AUTOSAR XML (schema 4-3-0)
standard types defined: sint16, uint16, uint8, sint16_DataConstr, uint16_DataConstr, uint8_DataConstr, boolean
package /IoHwAb/Interface
  client server interface IoHwAb_IoSigAdc
    operation Adc_Get: possible-error=E_NOT_OK
      arg id_u16: type=ImplementationDataTypes/uint16, direction=IN, server-argument-impl-policy=USE-ARGUMENT-TYPE
      arg val_s16: type=sint16, direction=OUT, server-argument-impl-policy=USE-ARGUMENT-TYPE
    operation AdcFac_Get: possible-error=E_NOT_OK
      arg id_u16: type=ImplementationDataTypes/uint16, direction=IN, server-argument-impl-policy=USE-ARGUMENT-TYPE
      arg val_s16: type=sint16, direction=OUT, server-argument-impl-policy=USE-ARGUMENT-TYPE
    operation AdcVRMBatt_Get: possible-error=E_NOT_OK
      arg id_u16: type=ImplementationDataTypes/uint16, direction=IN, server-argument-impl-policy=USE-ARGUMENT-TYPE
      arg val_u8: type=ImplementationDataTypes/uint8, direction=OUT, server-argument-impl-policy=USE-ARGUMENT-TYPE
    error E_NOT_OK: error-code=1
package /UAES/ASW/ApplicationDataTypes
  app type Fac_q0p001_u16: category=VALUE, sw-calibration-access=READ-WRITE, compu {phys=raw*0.001}, range phys 0..65.535
package /UAES/ASW/CompuMethods
  compu method CM_boolean: 0=FALSE, 1=TRUE
package /UAES/ASW/DataConstrs
  range DC_boolean: raw 0..1
  range DC_uint16: raw 0..65535
  range DC_uint8: raw 0..255
package /UAES/ASW/DataTypeMappingSets
  data type mapping set DTMS_PwrModMngt_DD: data-type-map{application-data-type=Fac_q0p001_u16, implementation-data-type=ImplementationDataTypes/uint16}
package /UAES/ASW/PortInterfaces
  7 x sender receiver interface:
    BattU_buExcdLrgRng: invalidation-policy{data-element=BattU_buExcdLrgRng/Val, handle-invalid=DONT-INVALIDATE}
      data Val: sw-calibration-access=READ-ONLY, type=boolean
    BattU_VrmFac1: invalidation-policy{data-element=BattU_VrmFac1/Val, handle-invalid=DONT-INVALIDATE}
      data Val: sw-calibration-access=READ-ONLY, type=Fac_q0p001_u16
    BattU_VrmFac2: invalidation-policy{data-element=BattU_VrmFac2/Val, handle-invalid=DONT-INVALIDATE}
      data Val: sw-calibration-access=READ-ONLY, type=Fac_q0p001_u16
    BattU_VrmFac3: invalidation-policy{data-element=BattU_VrmFac3/Val, handle-invalid=DONT-INVALIDATE}
      data Val: sw-calibration-access=READ-ONLY, type=Fac_q0p001_u16
    gPwrModMngt_u8RLSeatOccpdSwt: invalidation-policy{data-element=gPwrModMngt_u8RLSeatOccpdSwt/Val, handle-invalid=DONT-INVALIDATE}
      data Val: sw-calibration-access=READ-ONLY, type=ImplementationDataTypes/uint8
    gPwrModMngt_u8RMSeatOccpdSwt: invalidation-policy{data-element=gPwrModMngt_u8RMSeatOccpdSwt/Val, handle-invalid=DONT-INVALIDATE}
      data Val: sw-calibration-access=READ-ONLY, type=ImplementationDataTypes/uint8
    gPwrModMngt_u8RRSeatOccpdSwt: invalidation-policy{data-element=gPwrModMngt_u8RRSeatOccpdSwt/Val, handle-invalid=DONT-INVALIDATE}
      data Val: sw-calibration-access=READ-ONLY, type=ImplementationDataTypes/uint8
package /UAES/ASW/SwComponentTypes
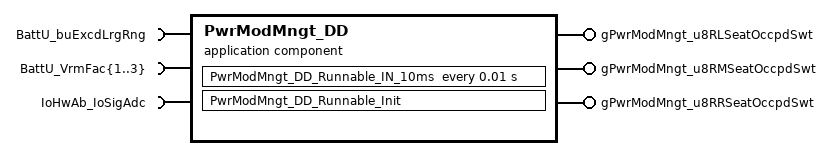
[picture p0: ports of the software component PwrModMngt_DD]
  application sw component type PwrModMngt_DD
    provide port gPwrModMngt_u8RLSeatOccpdSwt: nonqueued-sender-com-spec=data-element=gPwrModMngt_u8RLSeatOccpdSwt/Val, provided-interface=gPwrModMngt_u8RLSeatOccpdSwt
    provide port gPwrModMngt_u8RMSeatOccpdSwt: nonqueued-sender-com-spec=data-element=gPwrModMngt_u8RMSeatOccpdSwt/Val, provided-interface=gPwrModMngt_u8RMSeatOccpdSwt
    provide port gPwrModMngt_u8RRSeatOccpdSwt: nonqueued-sender-com-spec=data-element=gPwrModMngt_u8RRSeatOccpdSwt/Val, provided-interface=gPwrModMngt_u8RRSeatOccpdSwt
    5 x require port:
      BattU_buExcdLrgRng: nonqueued-receiver-com-spec{data-element=BattU_buExcdLrgRng/Val, filter=data-filter-type=ALWAYS, init-value=0}, required-interface=BattU_buExcdLrgRng
      BattU_VrmFac{1..3}: nonqueued-receiver-com-spec{data-element=BattU_VrmFac{1..3}/Val, filter=data-filter-type=ALWAYS, init-value=0}, required-interface=BattU_VrmFac{1..3}
      IoHwAb_IoSigAdc: required-com-specs=[Adc_Get, AdcFac_Get, AdcVRMBatt_Get], required-interface=IoHwAb_IoSigAdc
    behavior PwrModMngt_DD_InternalBehavior: data-type-mapping=DTMS_PwrModMngt_DD
      timing event TMT_PwrModMngt_DD_Runnable_IN_10ms: start-on-event=PwrModMngt_DD_Runnable_IN_10ms, period=0.01
      init event PwrModMngt_DD_Runnable_InitEvent: start-on-event=PwrModMngt_DD_Runnable_Init
      runnable PwrModMngt_DD_Runnable_IN_10ms
        data-receive-point-by-arguments:
          4 x access:
            IN_BattU_buExcdLrgRng_Val: accessed-variable=BattU_buExcdLrgRng.Val
            IN_BattU_VrmFac{1..3}_Val: accessed-variable=BattU_VrmFac{1..3}.Val
        data-send-points:
          access OUT_gPwrModMngt_u8RLSeatOccpdSwt_Val: accessed-variable=gPwrModMngt_u8RLSeatOccpdSwt.Val
          access OUT_gPwrModMngt_u8RMSeatOccpdSwt_Val: accessed-variable=gPwrModMngt_u8RMSeatOccpdSwt.Val
          access OUT_gPwrModMngt_u8RRSeatOccpdSwt_Val: accessed-variable=gPwrModMngt_u8RRSeatOccpdSwt.Val
        sync call SC_IoHwAb_IoSigAdc_AdcFac_Get: operation=IoHwAb_IoSigAdc.AdcFac_Get, timeout=0
        sync call SC_IoHwAb_IoSigAdc_AdcVRMBatt_Get: operation=IoHwAb_IoSigAdc.AdcVRMBatt_Get, timeout=0
      runnable PwrModMngt_DD_Runnable_Init
  swc implementation PwrModMngt_DD_Implementation: behavior=PwrModMngt_DD_InternalBehavior
    code-descriptors:
      code Default: artifact-descriptors=autosar-engineering-object={short-label=Default, category=SWSRC}
package /UAES/ASW/Units
  unit NoUnit: factor-si-to-unit=1, offset-si-to-unit=0
